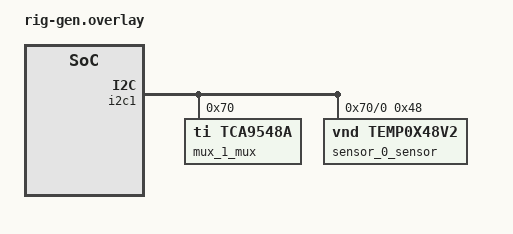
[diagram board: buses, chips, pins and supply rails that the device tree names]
/* generated by rigc — do not edit; the rig file is the source of truth (R3)
 * rig: shield_rev_family  board: nucleo_f401re/stm32f401xe/rig
 */

&i2c1 {
	mux_1_mux: mux@70 {
		compatible = "ti,tca9548a";
		reg = <0x70>;
		#address-cells = <1>;
		#size-cells = <0>;
		channel@0 {
			reg = <0>;
			#address-cells = <1>;
			#size-cells = <0>;
			sensor_0_sensor: sensor@48 {
				compatible = "vnd,temp0x48v2";
				reg = <0x48>;
				status = "okay";
			};
		};
	};
};
